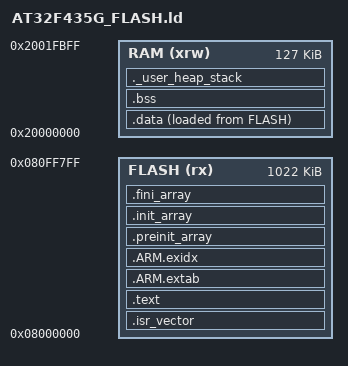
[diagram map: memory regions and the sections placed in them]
ENTRY(Reset_Handler)
MEMORY
{
  /* 1 MiB AT32F435G; final 2 KiB erase page is settings only. */
  FLASH (rx) : ORIGIN = 0x08000000, LENGTH = 1022K
  /* Use only the guaranteed first 128 KiB, regardless of USD SRAM split.
   * Final 1 KiB is excluded for the reboot-to-ROM request. */
  RAM (xrw) : ORIGIN = 0x20000000, LENGTH = 127K
}
_estack = ORIGIN(RAM) + LENGTH(RAM);
_Min_Heap_Size = 0x200;
_Min_Stack_Size = 0x1000;
SECTIONS
{
  .isr_vector : { . = ALIGN(4); KEEP(*(.isr_vector)) } > FLASH
  .text : { . = ALIGN(4); *(.text*) *(.rodata*) KEEP(*(.init)) KEEP(*(.fini)) . = ALIGN(4); _etext = .; } > FLASH
  .ARM.extab : { *(.ARM.extab*) } > FLASH
  .ARM.exidx : { __exidx_start = .; *(.ARM.exidx*) __exidx_end = .; } > FLASH
  .preinit_array : { PROVIDE_HIDDEN(__preinit_array_start = .); KEEP(*(.preinit_array*)) PROVIDE_HIDDEN(__preinit_array_end = .); } > FLASH
  .init_array : { PROVIDE_HIDDEN(__init_array_start = .); KEEP(*(SORT(.init_array.*))) KEEP(*(.init_array*)) PROVIDE_HIDDEN(__init_array_end = .); } > FLASH
  .fini_array : { PROVIDE_HIDDEN(__fini_array_start = .); KEEP(*(SORT(.fini_array.*))) KEEP(*(.fini_array*)) PROVIDE_HIDDEN(__fini_array_end = .); } > FLASH
  _sidata = LOADADDR(.data);
  .data : { . = ALIGN(4); _sdata = .; *(.data*) . = ALIGN(4); _edata = .; } > RAM AT> FLASH
  .bss : { . = ALIGN(4); _sbss = .; *(.bss*) *(COMMON) . = ALIGN(4); _ebss = .; } > RAM
  ._user_heap_stack : { . = ALIGN(8); PROVIDE(end = .); PROVIDE(_end = .); . += _Min_Heap_Size; . += _Min_Stack_Size; . = ALIGN(8); } > RAM
  /DISCARD/ : { *(.note.GNU-stack) }
}
ASSERT(_estack <= 0x2001FC00, "AT32 RAM overlaps reserved boot request area")
